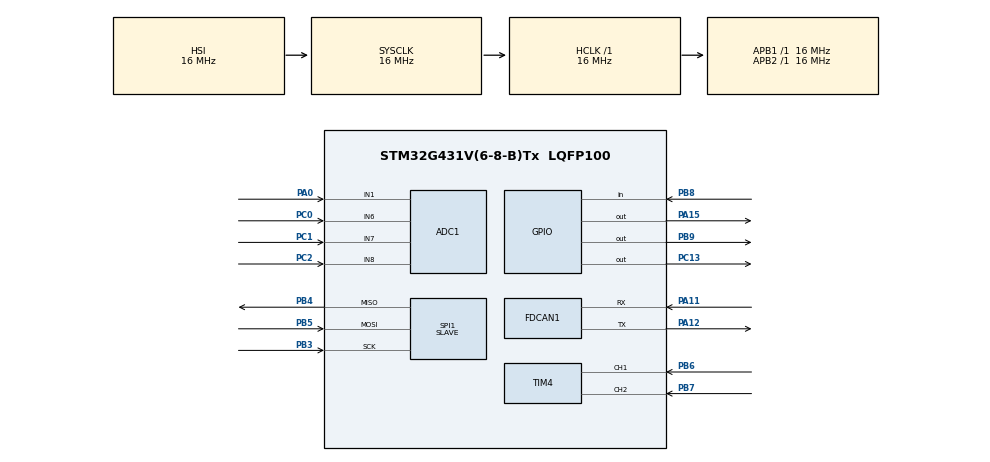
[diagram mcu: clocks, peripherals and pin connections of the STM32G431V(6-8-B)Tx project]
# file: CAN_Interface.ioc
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ADC1.Channel-0\#ChannelRegularConversion=ADC_CHANNEL_1
ADC1.NbrOfConversionFlag=1
ADC1.OffsetNumber-0\#ChannelRegularConversion=ADC_OFFSET_NONE
ADC1.Rank-0\#ChannelRegularConversion=1
ADC1.SamplingTime-0\#ChannelRegularConversion=ADC_SAMPLETIME_2CYCLES_5
ADC1.master=1
FDCAN1.CalculateBaudRateNominal=333333
FDCAN1.CalculateTimeBitNominal=3000
FDCAN1.CalculateTimeQuantumNominal=1000.0
Mcu.Family=STM32G4
Mcu.Name=STM32G431V(6-8-B)Tx
Mcu.Package=LQFP100
NVIC.PriorityGroup=NVIC_PRIORITYGROUP_4
PA0.Mode=IN1-Single-Ended
PA0.Signal=ADC1_IN1
PA11.Mode=FDCAN_Activate
PA11.Signal=FDCAN1_RX
PA12.Mode=FDCAN_Activate
PA12.Signal=FDCAN1_TX
PA13.Signal=SYS_JTMS-SWDIO
PA14.Signal=SYS_JTCK-SWCLK
PA15.Signal=GPIO_Output
PB3.Mode=Full_Duplex_Slave
PB3.Signal=SPI1_SCK
PB4.Mode=Full_Duplex_Slave
PB4.Signal=SPI1_MISO
PB5.Mode=Full_Duplex_Slave
PB5.Signal=SPI1_MOSI
PB6.Signal=S_TIM4_CH1
PB7.Signal=S_TIM4_CH2
PB8-BOOT0.Signal=GPIO_Input
PB9.Signal=GPIO_Output
PC0.Mode=IN6-Single-Ended
PC0.Signal=ADC1_IN6
PC1.Mode=IN7-Single-Ended
PC1.Signal=ADC1_IN7
PC13.Signal=GPIO_Output
PC2.Mode=IN8-Single-Ended
PC2.Signal=ADC1_IN8
PC4.Signal=USART1_TX
PC5.Signal=USART1_RX
PF0-OSC_IN.Mode=HSE-External-Oscillator
PF0-OSC_IN.Signal=RCC_OSC_IN
PF1-OSC_OUT.Mode=HSE-External-Oscillator
PF1-OSC_OUT.Signal=RCC_OSC_OUT
ProjectManager.HeapSize=0x200
ProjectManager.StackSize=0x400
ProjectManager.TargetToolchain=STM32CubeIDE
RCC.AHBFreq_Value=16000000
RCC.APB1Freq_Value=16000000
RCC.APB1TimFreq_Value=16000000
RCC.APB2Freq_Value=16000000
RCC.APB2TimFreq_Value=16000000
RCC.CortexFreq_Value=16000000
RCC.EXTERNAL_CLOCK_VALUE=12288000
RCC.HCLKFreq_Value=16000000
RCC.HSE_VALUE=8000000
RCC.HSI48_VALUE=48000000
RCC.HSI_VALUE=16000000
RCC.LSE_VALUE=32768
RCC.SYSCLKFreq_VALUE=16000000
RCC.USBFreq_Value=64000000
RCC.VCOOutputFreq_Value=128000000
SH.S_TIM4_CH1.0=TIM4_CH1,Encoder_Interface
SH.S_TIM4_CH2.0=TIM4_CH2,Encoder_Interface
SPI1.Direction=SPI_DIRECTION_2LINES
SPI1.Mode=SPI_MODE_SLAVE
SPI1.VirtualType=VM_SLAVE
VP_SYS_VS_DBSignals.Mode=DisableDeadBatterySignals
VP_TIM8_VS_ClockSourceINT.Mode=Internal
board=custom

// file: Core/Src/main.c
/* USER CODE BEGIN Header */
/**
  ******************************************************************************
  * @file           : main.c
  * @brief          : Main program body
  ******************************************************************************
  * @attention
  *
  * Copyright (c) 2026 STMicroelectronics.
  * All rights reserved.
  *
  * This software is licensed under terms that can be found in the LICENSE file
  * in the root directory of this software component.
  * If no LICENSE file comes with this software, it is provided AS-IS.
  *
  ******************************************************************************
  */
/* USER CODE END Header */
#include "main.h"
#include "interface.h"

#include <stdbool.h>
#include <string.h>

ADC_HandleTypeDef hadc1;

FDCAN_HandleTypeDef hfdcan1;

SPI_HandleTypeDef hspi1;

TIM_HandleTypeDef htim4;
TIM_HandleTypeDef htim8;

void SystemClock_Config(void);
static void MX_GPIO_Init(void);
static void MX_ADC1_Init(void);
static void MX_FDCAN1_Init(void);
static void MX_SPI1_Init(void);
static void MX_TIM4_Init(void);
static void MX_TIM8_Init(void);
static void process_CAN_frame(const uint8_t *rx);

/* USER CODE BEGIN PFP */
static void FDCAN_Config(void):
/* USER CODE END PFP */

int main(void)
{

  /* MCU Configuration--------------------------------------------------------*/

  /* Reset of all peripherals, Initializes the Flash interface and the Systick. */
  HAL_Init();

  /* Configure the system clock */
  SystemClock_Config();

  /* Initialize all configured peripherals */
  MX_GPIO_Init();
  MX_ADC1_Init();
  MX_FDCAN1_Init();
  MX_SPI1_Init();
  MX_TIM4_Init();
  MX_TIM8_Init();

  /* Infinite loop */
  while (1)
  {

  }
}

void SystemClock_Config(void)
{
  RCC_OscInitTypeDef RCC_OscInitStruct = {0};
  RCC_ClkInitTypeDef RCC_ClkInitStruct = {0};

  /** Configure the main internal regulator output voltage
  */
  HAL_PWREx_ControlVoltageScaling(PWR_REGULATOR_VOLTAGE_SCALE1);

  /** Initializes the RCC Oscillators according to the specified parameters
  * in the RCC_OscInitTypeDef structure.
  */
  RCC_OscInitStruct.OscillatorType = RCC_OSCILLATORTYPE_HSI;
  RCC_OscInitStruct.HSIState = RCC_HSI_ON;
  RCC_OscInitStruct.HSICalibrationValue = RCC_HSICALIBRATION_DEFAULT;
  RCC_OscInitStruct.PLL.PLLState = RCC_PLL_NONE;
  if (HAL_RCC_OscConfig(&RCC_OscInitStruct) != HAL_OK)
  {
    Error_Handler();
  }

  /** Initializes the CPU, AHB and APB buses clocks
  */
  RCC_ClkInitStruct.ClockType = RCC_CLOCKTYPE_HCLK|RCC_CLOCKTYPE_SYSCLK
                              |RCC_CLOCKTYPE_PCLK1|RCC_CLOCKTYPE_PCLK2;
  RCC_ClkInitStruct.SYSCLKSource = RCC_SYSCLKSOURCE_HSI;
  RCC_ClkInitStruct.AHBCLKDivider = RCC_SYSCLK_DIV1;
  RCC_ClkInitStruct.APB1CLKDivider = RCC_HCLK_DIV1;
  RCC_ClkInitStruct.APB2CLKDivider = RCC_HCLK_DIV1;

  if (HAL_RCC_ClockConfig(&RCC_ClkInitStruct, FLASH_LATENCY_0) != HAL_OK)
  {
    Error_Handler();
  }
}

static void MX_ADC1_Init(void)
{

  ADC_MultiModeTypeDef multimode = {0};
  ADC_ChannelConfTypeDef sConfig = {0};

  /** Common config
  */
  hadc1.Instance = ADC1;
  hadc1.Init.ClockPrescaler = ADC_CLOCK_SYNC_PCLK_DIV2;
  hadc1.Init.Resolution = ADC_RESOLUTION_12B;
  hadc1.Init.DataAlign = ADC_DATAALIGN_RIGHT;
  hadc1.Init.GainCompensation = 0;
  hadc1.Init.ScanConvMode = ADC_SCAN_DISABLE;
  hadc1.Init.EOCSelection = ADC_EOC_SINGLE_CONV;
  hadc1.Init.LowPowerAutoWait = DISABLE;
  hadc1.Init.ContinuousConvMode = DISABLE;
  hadc1.Init.NbrOfConversion = 1;
  hadc1.Init.DiscontinuousConvMode = DISABLE;
  hadc1.Init.ExternalTrigConv = ADC_SOFTWARE_START;
  hadc1.Init.ExternalTrigConvEdge = ADC_EXTERNALTRIGCONVEDGE_NONE;
  hadc1.Init.DMAContinuousRequests = DISABLE;
  hadc1.Init.Overrun = ADC_OVR_DATA_PRESERVED;
  hadc1.Init.OversamplingMode = DISABLE;
  if (HAL_ADC_Init(&hadc1) != HAL_OK)
  {
    Error_Handler();
  }

  /** Configure the ADC multi-mode
  */
  multimode.Mode = ADC_MODE_INDEPENDENT;
  if (HAL_ADCEx_MultiModeConfigChannel(&hadc1, &multimode) != HAL_OK)
  {
    Error_Handler();
  }

  /** Configure Regular Channel
  */
  sConfig.Channel = ADC_CHANNEL_1;
  sConfig.Rank = ADC_REGULAR_RANK_1;
  sConfig.SamplingTime = ADC_SAMPLETIME_2CYCLES_5;
  sConfig.SingleDiff = ADC_SINGLE_ENDED;
  sConfig.OffsetNumber = ADC_OFFSET_NONE;
  sConfig.Offset = 0;
  if (HAL_ADC_ConfigChannel(&hadc1, &sConfig) != HAL_OK)
  {
    Error_Handler();
  }

}

static void MX_FDCAN1_Init(void)
{

  hfdcan1.Instance = FDCAN1;
  hfdcan1.Init.ClockDivider = FDCAN_CLOCK_DIV1;
  hfdcan1.Init.FrameFormat = FDCAN_FRAME_CLASSIC;
  hfdcan1.Init.Mode = FDCAN_MODE_NORMAL;
  hfdcan1.Init.AutoRetransmission = DISABLE;
  hfdcan1.Init.TransmitPause = DISABLE;
  hfdcan1.Init.ProtocolException = DISABLE;
  hfdcan1.Init.NominalPrescaler = 16;
  hfdcan1.Init.NominalSyncJumpWidth = 1;
  hfdcan1.Init.NominalTimeSeg1 = 1;
  hfdcan1.Init.NominalTimeSeg2 = 1;
  hfdcan1.Init.DataPrescaler = 1;
  hfdcan1.Init.DataSyncJumpWidth = 1;
  hfdcan1.Init.DataTimeSeg1 = 1;
  hfdcan1.Init.DataTimeSeg2 = 1;
  hfdcan1.Init.StdFiltersNbr = 0;
  hfdcan1.Init.ExtFiltersNbr = 0;
  hfdcan1.Init.TxFifoQueueMode = FDCAN_TX_FIFO_OPERATION;
  if (HAL_FDCAN_Init(&hfdcan1) != HAL_OK)
  {
    Error_Handler();
  }

}

static void MX_SPI1_Init(void)
{

  /* SPI1 parameter configuration*/
  hspi1.Instance = SPI1;
  hspi1.Init.Mode = SPI_MODE_SLAVE;
  hspi1.Init.Direction = SPI_DIRECTION_2LINES;
  hspi1.Init.DataSize = SPI_DATASIZE_4BIT;
  hspi1.Init.CLKPolarity = SPI_POLARITY_LOW;
  hspi1.Init.CLKPhase = SPI_PHASE_1EDGE;
  hspi1.Init.NSS = SPI_NSS_SOFT;
  hspi1.Init.FirstBit = SPI_FIRSTBIT_MSB;
  hspi1.Init.TIMode = SPI_TIMODE_DISABLE;
  hspi1.Init.CRCCalculation = SPI_CRCCALCULATION_DISABLE;
  hspi1.Init.CRCPolynomial = 7;
  hspi1.Init.CRCLength = SPI_CRC_LENGTH_DATASIZE;
  hspi1.Init.NSSPMode = SPI_NSS_PULSE_DISABLE;
  if (HAL_SPI_Init(&hspi1) != HAL_OK)
  {
    Error_Handler();
  }

}

static void MX_TIM4_Init(void)
{

  TIM_Encoder_InitTypeDef sConfig = {0};
  TIM_MasterConfigTypeDef sMasterConfig = {0};

  htim4.Instance = TIM4;
  htim4.Init.Prescaler = 0;
  htim4.Init.CounterMode = TIM_COUNTERMODE_UP;
  htim4.Init.Period = 65535;
  htim4.Init.ClockDivision = TIM_CLOCKDIVISION_DIV1;
  htim4.Init.AutoReloadPreload = TIM_AUTORELOAD_PRELOAD_DISABLE;
  sConfig.EncoderMode = TIM_ENCODERMODE_TI1;
  sConfig.IC1Polarity = TIM_ICPOLARITY_RISING;
  sConfig.IC1Selection = TIM_ICSELECTION_DIRECTTI;
  sConfig.IC1Prescaler = TIM_ICPSC_DIV1;
  sConfig.IC1Filter = 0;
  sConfig.IC2Polarity = TIM_ICPOLARITY_RISING;
  sConfig.IC2Selection = TIM_ICSELECTION_DIRECTTI;
  sConfig.IC2Prescaler = TIM_ICPSC_DIV1;
  sConfig.IC2Filter = 0;
  if (HAL_TIM_Encoder_Init(&htim4, &sConfig) != HAL_OK)
  {
    Error_Handler();
  }
  sMasterConfig.MasterOutputTrigger = TIM_TRGO_RESET;
  sMasterConfig.MasterSlaveMode = TIM_MASTERSLAVEMODE_DISABLE;
  if (HAL_TIMEx_MasterConfigSynchronization(&htim4, &sMasterConfig) != HAL_OK)
  {
    Error_Handler();
  }

}

static void MX_TIM8_Init(void)
{

  TIM_ClockConfigTypeDef sClockSourceConfig = {0};
  TIM_MasterConfigTypeDef sMasterConfig = {0};

  htim8.Instance = TIM8;
  htim8.Init.Prescaler = 0;
  htim8.Init.CounterMode = TIM_COUNTERMODE_UP;
  htim8.Init.Period = 65535;
  htim8.Init.ClockDivision = TIM_CLOCKDIVISION_DIV1;
  htim8.Init.RepetitionCounter = 0;
  htim8.Init.AutoReloadPreload = TIM_AUTORELOAD_PRELOAD_DISABLE;
  if (HAL_TIM_Base_Init(&htim8) != HAL_OK)
  {
    Error_Handler();
  }
  sClockSourceConfig.ClockSource = TIM_CLOCKSOURCE_INTERNAL;
  if (HAL_TIM_ConfigClockSource(&htim8, &sClockSourceConfig) != HAL_OK)
  {
    Error_Handler();
  }
  sMasterConfig.MasterOutputTrigger = TIM_TRGO_RESET;
  sMasterConfig.MasterOutputTrigger2 = TIM_TRGO2_RESET;
  sMasterConfig.MasterSlaveMode = TIM_MASTERSLAVEMODE_DISABLE;
  if (HAL_TIMEx_MasterConfigSynchronization(&htim8, &sMasterConfig) != HAL_OK)
  {
    Error_Handler();
  }

}

static void MX_GPIO_Init(void)
{
  GPIO_InitTypeDef GPIO_InitStruct = {0};

  /* GPIO Ports Clock Enable */
  __HAL_RCC_GPIOC_CLK_ENABLE();
  __HAL_RCC_GPIOF_CLK_ENABLE();
  __HAL_RCC_GPIOA_CLK_ENABLE();
  __HAL_RCC_GPIOB_CLK_ENABLE();

  /*Configure GPIO pin Output Level */
  HAL_GPIO_WritePin(GPIOC, GPIO_PIN_13, GPIO_PIN_RESET);

  /*Configure GPIO pin Output Level */
  HAL_GPIO_WritePin(GPIOA, GPIO_PIN_15, GPIO_PIN_RESET);

  /*Configure GPIO pin Output Level */
  HAL_GPIO_WritePin(GPIOB, GPIO_PIN_9, GPIO_PIN_RESET);

  /*Configure GPIO pin : PC13 */
  GPIO_InitStruct.Pin = GPIO_PIN_13;
  GPIO_InitStruct.Mode = GPIO_MODE_OUTPUT_PP;
  GPIO_InitStruct.Pull = GPIO_NOPULL;
  GPIO_InitStruct.Speed = GPIO_SPEED_FREQ_LOW;
  HAL_GPIO_Init(GPIOC, &GPIO_InitStruct);

  /*Configure GPIO pins : PC4 PC5 */
  GPIO_InitStruct.Pin = GPIO_PIN_4|GPIO_PIN_5;
  GPIO_InitStruct.Mode = GPIO_MODE_AF_PP;
  GPIO_InitStruct.Pull = GPIO_NOPULL;
  GPIO_InitStruct.Speed = GPIO_SPEED_FREQ_LOW;
  GPIO_InitStruct.Alternate = GPIO_AF7_USART1;
  HAL_GPIO_Init(GPIOC, &GPIO_InitStruct);

  /*Configure GPIO pin : PA15 */
  GPIO_InitStruct.Pin = GPIO_PIN_15;
  GPIO_InitStruct.Mode = GPIO_MODE_OUTPUT_PP;
  GPIO_InitStruct.Pull = GPIO_NOPULL;
  GPIO_InitStruct.Speed = GPIO_SPEED_FREQ_LOW;
  HAL_GPIO_Init(GPIOA, &GPIO_InitStruct);

  /*Configure GPIO pin : PB8 */
  GPIO_InitStruct.Pin = GPIO_PIN_8;
  GPIO_InitStruct.Mode = GPIO_MODE_INPUT;
  GPIO_InitStruct.Pull = GPIO_NOPULL;
  HAL_GPIO_Init(GPIOB, &GPIO_InitStruct);

  /*Configure GPIO pin : PB9 */
  GPIO_InitStruct.Pin = GPIO_PIN_9;
  GPIO_InitStruct.Mode = GPIO_MODE_OUTPUT_PP;
  GPIO_InitStruct.Pull = GPIO_NOPULL;
  GPIO_InitStruct.Speed = GPIO_SPEED_FREQ_LOW;
  HAL_GPIO_Init(GPIOB, &GPIO_InitStruct);

}

/* USER CODE BEGIN 4 */

static void FDCAN_Config(void)
{
	FDCAN_FilterTypeDef sFilterConfig;
	 /* Configure Rx filter */
	 sFilterConfig.IdType = FDCAN_STANDARD_ID;
	 sFilterConfig.FilterIndex = 0;
	 sFilterConfig.FilterType = FDCAN_FILTER_RANGE;
	 sFilterConfig.FilterConfig = FDCAN_FILTER_TO_RXFIFO0;
	 sFilterConfig.FilterID1 = 0x321;
	 sFilterConfig.FilterID2 = 0x7FF;
	 if (HAL_FDCAN_ConfigFilter(&hfdcan1, &sFilterConfig) != HAL_OK)
	 {
	 Error_Handler();

}
/* USER CODE END 4 */

void Error_Handler(void)
{
  __disable_irq();
  while (1)
  {
  }
}
